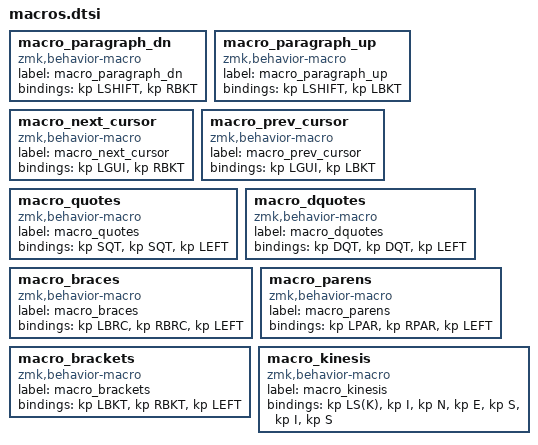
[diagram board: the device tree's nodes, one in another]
macro_paragraph_dn: macro_paragraph_dn{
compatible = "zmk,behavior-macro";
label = "macro_paragraph_dn";
#binding-cells = <0>;
bindings = <&kp LSHIFT>, <&kp RBKT>;
};
macro_paragraph_up: macro_paragraph_up{
compatible = "zmk,behavior-macro";
label = "macro_paragraph_up";
#binding-cells = <0>;
bindings = <&kp LSHIFT>, <&kp LBKT>;
};
macro_next_cursor: macro_next_cursor{
compatible = "zmk,behavior-macro";
label = "macro_next_cursor";
#binding-cells = <0>;
bindings = <&kp LGUI>, <&kp RBKT>;
};
macro_prev_cursor: macro_prev_cursor{
compatible = "zmk,behavior-macro";
label = "macro_prev_cursor";
#binding-cells = <0>;
bindings = <&kp LGUI>, <&kp LBKT>;
};
macro_quotes: macro_quotes{
compatible = "zmk,behavior-macro";
label = "macro_quotes";
#binding-cells = <0>;
bindings = <&kp SQT>, <&kp SQT>, <&kp LEFT>;
};
macro_dquotes: macro_dquotes{
compatible = "zmk,behavior-macro";
label = "macro_dquotes";
#binding-cells = <0>;
bindings = <&kp DQT>, <&kp DQT>, <&kp LEFT>;
};
macro_braces: macro_braces{
compatible = "zmk,behavior-macro";
label = "macro_braces";
#binding-cells = <0>;
bindings = <&kp LBRC>, <&kp RBRC>, <&kp LEFT>;
};
macro_parens: macro_parens{
compatible = "zmk,behavior-macro";
label = "macro_parens";
#binding-cells = <0>;
bindings = <&kp LPAR>, <&kp RPAR>, <&kp LEFT>;
};
macro_brackets: macro_brackets{
compatible = "zmk,behavior-macro";
label = "macro_brackets";
#binding-cells = <0>;
bindings = <&kp LBKT>, <&kp RBKT>, <&kp LEFT>;
};
macro_kinesis: macro_kinesis{
compatible = "zmk,behavior-macro";
label = "macro_kinesis";
#binding-cells = <0>;
bindings = <&kp LS(K)>, <&kp I>, <&kp N>, <&kp E>, <&kp S>, <&kp I>, <&kp S>;
};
